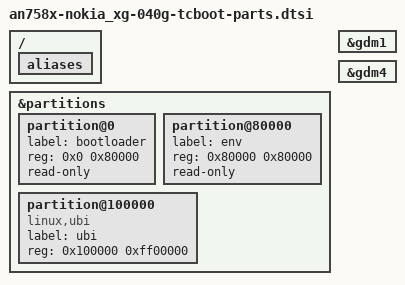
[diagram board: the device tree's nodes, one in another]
// SPDX-License-Identifier: GPL-2.0-only OR MIT

/ {
	aliases {
		/delete-property/ label-mac-device;
	};
};

&partitions {
	partition@0 {
		label = "bootloader";
		reg = <0x0 0x80000>;
		read-only;
	};

	partition@80000 {
		label = "env";
		reg = <0x80000 0x80000>;
		read-only;
	};

	partition@100000 {
		label = "ubi";
		reg = <0x100000 0xff00000>;
		compatible = "linux,ubi";
	};
};

/* The tcboot layout stores the Ethernet address in the environment. */
&gdm1 {
	/delete-property/ nvmem-cell-names;
	/delete-property/ nvmem-cells;
};

&gdm4 {
	/delete-property/ nvmem-cell-names;
	/delete-property/ nvmem-cells;
};
